# STM32WB50_CM4 register map
File version: 1.4
CPU: CM4 r0p1, little endian, MPU, FPU, 4 interrupt priority bits
Registers are 32-bit, read-write, reset 0x0 unless marked. A register's access mark holds for its fields unless they carry their own. Offsets are from the block's base; [hi:lo] are bit positions; 'fields as' and 'values as' point back to an identical list.

## TIM16 — General purpose timers
Base 0x40014400
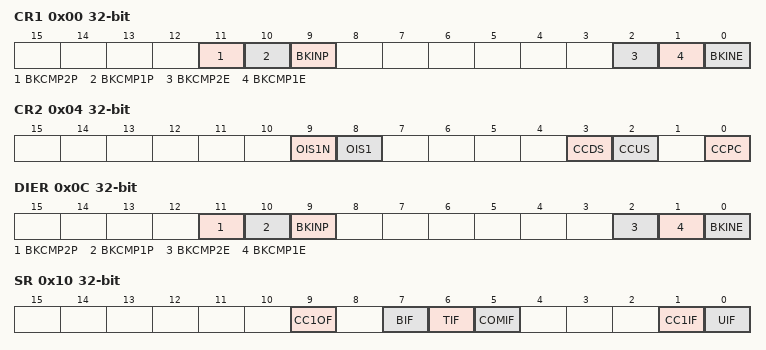
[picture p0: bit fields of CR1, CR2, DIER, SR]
0x00 CR1 — control register 1
  [11] BKCMP2P — BRK COMP2 input polarit
  [10] BKCMP1P — BRK COMP1 input polarity
  [9] BKINP — BRK BKIN input polarity
  [2] BKCMP2E — BRK COMP2 enable
  [1] BKCMP1E — BRK COMP1 enable
  [0] BKINE — BRK BKIN input enable
0x04 CR2 — control register 2
  [9] OIS1N — Output Idle state 1
  [8] OIS1 — Output Idle state 1
  [3] CCDS — Capture/compare DMA selection
  [2] CCUS — Capture/compare control update selection
  [0] CCPC — Capture/compare preloaded control
0x0C DIER — DMA/Interrupt enable register
  fields as CR1
0x10 SR — status register
  [9] CC1OF — Capture/Compare 1 overcapture flag
  [7] BIF — Break interrupt flag
  [6] TIF — Trigger interrupt flag
  [5] COMIF — COM interrupt flag
  [1] CC1IF — Capture/compare 1 interrupt flag
  [0] UIF — Update interrupt flag
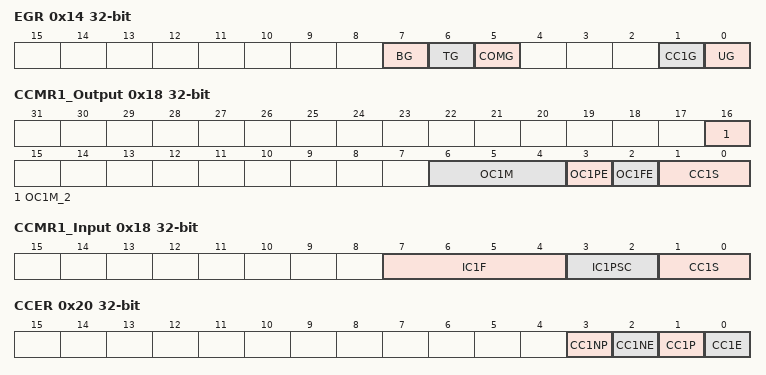
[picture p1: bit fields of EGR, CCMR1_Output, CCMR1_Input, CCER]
0x14 EGR wo — event generation register
  [7] BG — Break generation
  [6] TG — Trigger generation
  [5] COMG — Capture/Compare control update generation
  [1] CC1G — Capture/compare 1 generation
  [0] UG — Update generation
0x18 CCMR1_Output — capture/compare mode register (output mode)
  [16] OC1M_2 — Output Compare 1 mode
  [6:4] OC1M — Output Compare 1 mode
  [3] OC1PE — Output Compare 1 preload enable
  [2] OC1FE — Output Compare 1 fast enable
  [1:0] CC1S — Capture/Compare 1 selection
0x18 CCMR1_Input (alternate view of CCMR1_Output) — capture/compare mode register 1 (input mode)
  [7:4] IC1F — Input capture 1 filter
  [3:2] IC1PSC — Input capture 1 prescaler
  [1:0] CC1S — Capture/Compare 1 selection
0x20 CCER — capture/compare enable register
  [3] CC1NP — Capture/Compare 1 output Polarity
  [2] CC1NE — Capture/Compare 1 complementary output enable
  [1] CC1P — Capture/Compare 1 output Polarity
  [0] CC1E — Capture/Compare 1 output enable
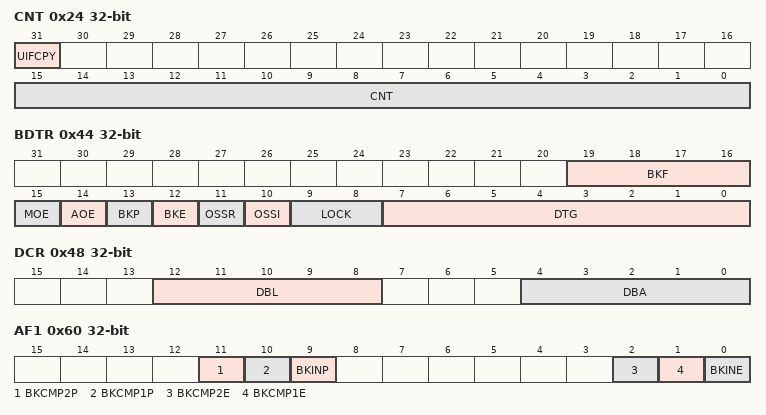
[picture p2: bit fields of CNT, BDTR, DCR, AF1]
0x24 CNT access per field — counter
  [31] UIFCPY ro — UIF Copy
  [15:0] CNT rw — counter value
0x28 PSC — prescaler
  [15:0] PSC — Prescaler value
0x2C ARR — auto-reload register
  [15:0] ARR — Auto-reload value
0x30 RCR — repetition counter register
  [7:0] REP — Repetition counter value
0x34 CCR1 — capture/compare register 1
  [15:0] CCR1 — Capture/Compare 1 value
0x44 BDTR — break and dead-time register
  [19:16] BKF — Break filter
  [15] MOE — Main output enable
  [14] AOE — Automatic output enable
  [13] BKP — Break polarity
  [12] BKE — Break enable
  [11] OSSR — Off-state selection for Run mode
  [10] OSSI — Off-state selection for Idle mode
  [9:8] LOCK — Lock configuration
  [7:0] DTG — Dead-time generator setup
0x48 DCR — DMA control register
  [12:8] DBL — DMA burst length
  [4:0] DBA — DMA base address
0x4C DMAR — DMA address for full transfer
  [15:0] DMAB — DMA register for burst accesses
0x50 OR — TIM16 option register 1
  [1:0] TI1_RMP — Input capture 1 remap
0x60 AF1 — TIM17 option register 1
  fields as CR1

## TIM17 — General purpose timers
Base 0x40014800
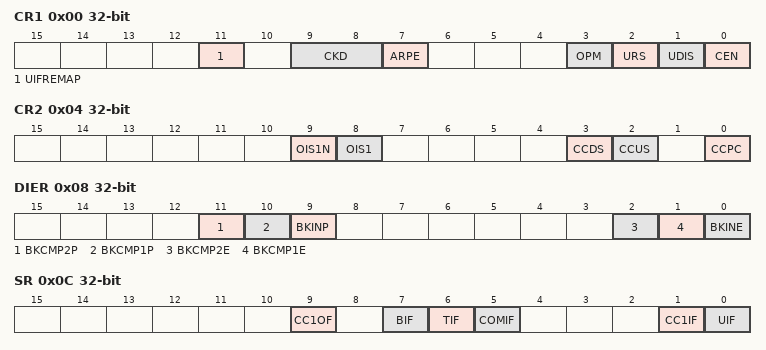
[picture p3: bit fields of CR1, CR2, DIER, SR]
0x00 CR1 — control register 1
  [11] UIFREMAP — UIF status bit remapping
  [9:8] CKD — Clock division
  [7] ARPE — Auto-reload preload enable
  [3] OPM — One-pulse mode
  [2] URS — Update request source
  [1] UDIS — Update disable
  [0] CEN — Counter enable
0x04 CR2 — control register 2
  [9] OIS1N — Output Idle state 1
  [8] OIS1 — Output Idle state 1
  [3] CCDS — Capture/compare DMA selection
  [2] CCUS — Capture/compare control update selection
  [0] CCPC — Capture/compare preloaded control
0x08 DIER — DMA/Interrupt enable register
  [11] BKCMP2P — BRK COMP2 input polarit
  [10] BKCMP1P — BRK COMP1 input polarity
  [9] BKINP — BRK BKIN input polarity
  [2] BKCMP2E — BRK COMP2 enable
  [1] BKCMP1E — BRK COMP1 enable
  [0] BKINE — BRK BKIN input enable
0x0C SR — status register
  [9] CC1OF — Capture/Compare 1 overcapture flag
  [7] BIF — Break interrupt flag
  [6] TIF — Trigger interrupt flag
  [5] COMIF — COM interrupt flag
  [1] CC1IF — Capture/compare 1 interrupt flag
  [0] UIF — Update interrupt flag
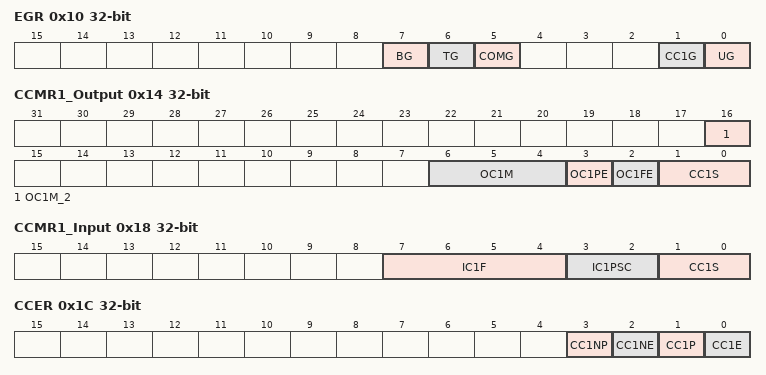
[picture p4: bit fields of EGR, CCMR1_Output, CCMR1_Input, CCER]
0x10 EGR wo — event generation register
  [7] BG — Break generation
  [6] TG — Trigger generation
  [5] COMG — Capture/Compare control update generation
  [1] CC1G — Capture/compare 1 generation
  [0] UG — Update generation
0x14 CCMR1_Output — capture/compare mode register (output mode)
  [16] OC1M_2 — Output Compare 1 mode
  [6:4] OC1M — Output Compare 1 mode
  [3] OC1PE — Output Compare 1 preload enable
  [2] OC1FE — Output Compare 1 fast enable
  [1:0] CC1S — Capture/Compare 1 selection
0x18 CCMR1_Input — capture/compare mode register 1 (input mode)
  [7:4] IC1F — Input capture 1 filter
  [3:2] IC1PSC — Input capture 1 prescaler
  [1:0] CC1S — Capture/Compare 1 selection
0x1C CCER — capture/compare enable register
  [3] CC1NP — Capture/Compare 1 output Polarity
  [2] CC1NE — Capture/Compare 1 complementary output enable
  [1] CC1P — Capture/Compare 1 output Polarity
  [0] CC1E — Capture/Compare 1 output enable
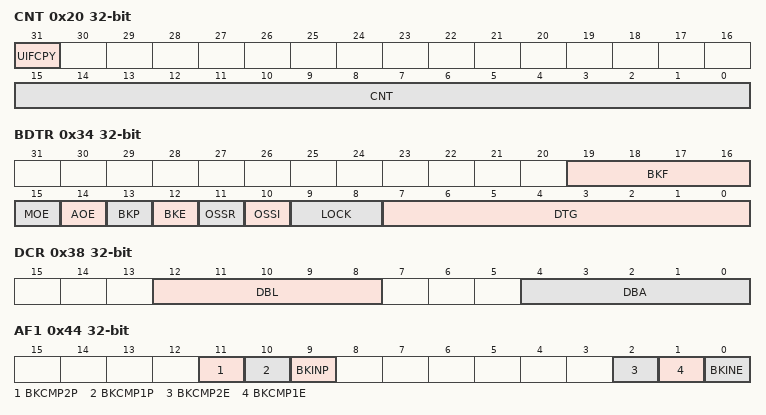
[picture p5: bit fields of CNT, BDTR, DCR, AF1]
0x20 CNT access per field — counter
  [31] UIFCPY ro — UIF Copy
  [15:0] CNT rw — counter value
0x24 PSC — prescaler
  [15:0] PSC — Prescaler value
0x28 ARR — auto-reload register
  [15:0] ARR — Auto-reload value
0x2C RCR — repetition counter register
  [7:0] REP — Repetition counter value
0x30 CCR1 — capture/compare register 1
  [15:0] CCR1 — Capture/Compare 1 value
0x34 BDTR — break and dead-time register
  [19:16] BKF — Break filter
  [15] MOE — Main output enable
  [14] AOE — Automatic output enable
  [13] BKP — Break polarity
  [12] BKE — Break enable
  [11] OSSR — Off-state selection for Run mode
  [10] OSSI — Off-state selection for Idle mode
  [9:8] LOCK — Lock configuration
  [7:0] DTG — Dead-time generator setup
0x38 DCR — DMA control register
  [12:8] DBL — DMA burst length
  [4:0] DBA — DMA base address
0x3C DMAR — DMA address for full transfer
  [15:0] DMAB — DMA register for burst accesses
0x40 OR — TIM16 option register 1
  [1:0] TI1_RMP — Input capture 1 remap
0x44 AF1 — TIM17 option register 1
  fields as DIER

## WWDG — System window watchdog
Base 0x40002C00
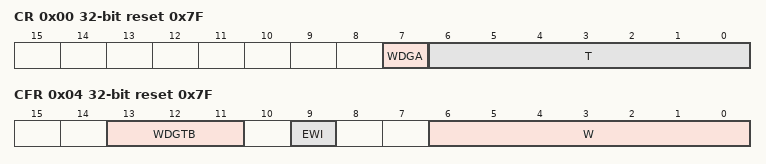
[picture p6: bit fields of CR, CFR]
0x00 CR reset 0x7F — Control register
  [7] WDGA — Activation bit
  [6:0] T — 7-bit counter (MSB to LSB)
0x04 CFR reset 0x7F — Configuration register
  [13:11] WDGTB — Timer base
  [9] EWI — Early wakeup interrupt
  [6:0] W — 7-bit window value
0x08 SR — Status register
  [0] EWIF — Early wakeup interrupt flag
